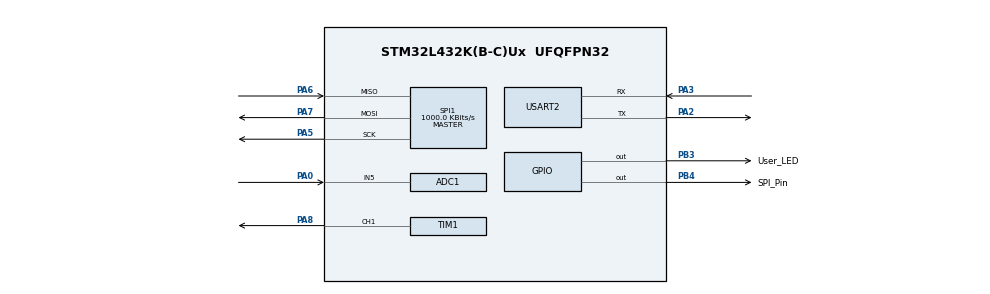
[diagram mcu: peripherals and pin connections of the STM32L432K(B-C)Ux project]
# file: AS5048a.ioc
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ADC1.Channel-1\#ChannelRegularConversion=ADC_CHANNEL_5
ADC1.NbrOfConversion=1
ADC1.NbrOfConversionFlag=1
ADC1.OffsetNumber-1\#ChannelRegularConversion=ADC_OFFSET_NONE
ADC1.Rank-1\#ChannelRegularConversion=1
ADC1.SamplingTime-1\#ChannelRegularConversion=ADC_SAMPLETIME_2CYCLES_5
ADC1.master=1
Mcu.Family=STM32L4
Mcu.Name=STM32L432K(B-C)Ux
Mcu.Package=UFQFPN32
NVIC.PriorityGroup=NVIC_PRIORITYGROUP_4
PA0.Signal=ADCx_IN5
PA2.Mode=Asynchronous
PA2.Signal=USART2_TX
PA3.Mode=Asynchronous
PA3.Signal=USART2_RX
PA5.Mode=Full_Duplex_Master
PA5.Signal=SPI1_SCK
PA6.Mode=Full_Duplex_Master
PA6.Signal=SPI1_MISO
PA7.Mode=Full_Duplex_Master
PA7.Signal=SPI1_MOSI
PA8.Signal=S_TIM1_CH1
PB3\ (JTDO-TRACESWO).GPIO_Label=User_LED
PB3\ (JTDO-TRACESWO).Signal=GPIO_Output
PB4\ (NJTRST).GPIO_Label=SPI_Pin
PB4\ (NJTRST).Signal=GPIO_Output
ProjectManager.HeapSize=0x200
ProjectManager.StackSize=0x400
ProjectManager.TargetToolchain=Makefile
RCC.ADCFreq_Value=32000000
RCC.HSE_VALUE=8000000
RCC.HSI48_VALUE=48000000
RCC.HSI_VALUE=16000000
RCC.LSE_VALUE=32768
RCC.MSI_VALUE=4000000
RCC.PLLSAI1N=16
RCC.USBFreq_Value=32000000
RCC.VCOOutputFreq_Value=32000000
SH.ADCx_IN5.0=ADC1_IN5,IN5-Single-Ended
SH.S_TIM1_CH1.0=TIM1_CH1,PWM Generation1 CH1
SPI1.BaudRatePrescaler=SPI_BAUDRATEPRESCALER_4
SPI1.CalculateBaudRate=1000.0 KBits/s
SPI1.DataSize=SPI_DATASIZE_16BIT
SPI1.Direction=SPI_DIRECTION_2LINES
SPI1.Mode=SPI_MODE_MASTER
SPI1.VirtualType=VM_MASTER
TIM1.Channel-PWM\ Generation1\ CH1=TIM_CHANNEL_1
TIM1.Prescaler=3
USART2.VirtualMode-Asynchronous=VM_ASYNC
VP_TIM1_VS_ClockSourceINT.Mode=Internal
board=custom

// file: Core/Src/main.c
/* USER CODE BEGIN Header */
/**
  ******************************************************************************
  * @file           : main.c
  * @brief          : Main program body
  ******************************************************************************
  * @attention
  *
  * Copyright (c) 2025 STMicroelectronics.
  * All rights reserved.
  *
  * This software is licensed under terms that can be found in the LICENSE file
  * in the root directory of this software component.
  * If no LICENSE file comes with this software, it is provided AS-IS.
  *
  ******************************************************************************
  */
/* USER CODE END Header */
#include "main.h"
#include "adc.h"
#include "spi.h"
#include "tim.h"
#include "usart.h"
#include "gpio.h"

/* USER CODE BEGIN Includes */
#include <string.h>
/* USER CODE END Includes */

void SystemClock_Config(void);

int main(void)
{

  /* MCU Configuration--------------------------------------------------------*/

  /* Reset of all peripherals, Initializes the Flash interface and the Systick. */
  HAL_Init();

  /* Configure the system clock */
  SystemClock_Config();

  /* Initialize all configured peripherals */
  MX_GPIO_Init();
  MX_ADC1_Init();
  MX_SPI1_Init();
  MX_TIM1_Init();
  MX_USART2_UART_Init();

  /* Infinite loop */
  /* USER CODE BEGIN WHILE */
  while (1)
  {
    // HAL_GPIO_WritePin(User_LED_GPIO_Port, User_LED_Pin, GPIO_PIN_SET);
    // HAL_Delay(1000);
    // HAL_GPIO_WritePin(User_LED_GPIO_Port, User_LED_Pin, GPIO_PIN_RESET);
    // HAL_Delay(1000);
    // uint8_t msg[] = "hello world!\n\r";
    // HAL_UART_Transmit(&huart2, msg, strlen((char*)msg), 100);

    /* USER CODE END WHILE */

  }
}

void SystemClock_Config(void)
{
  RCC_OscInitTypeDef RCC_OscInitStruct = {0};
  RCC_ClkInitTypeDef RCC_ClkInitStruct = {0};

  /** Configure the main internal regulator output voltage
  */
  if (HAL_PWREx_ControlVoltageScaling(PWR_REGULATOR_VOLTAGE_SCALE1) != HAL_OK)
  {
    Error_Handler();
  }

  /** Initializes the RCC Oscillators according to the specified parameters
  * in the RCC_OscInitTypeDef structure.
  */
  RCC_OscInitStruct.OscillatorType = RCC_OSCILLATORTYPE_MSI;
  RCC_OscInitStruct.MSIState = RCC_MSI_ON;
  RCC_OscInitStruct.MSICalibrationValue = 0;
  RCC_OscInitStruct.MSIClockRange = RCC_MSIRANGE_6;
  RCC_OscInitStruct.PLL.PLLState = RCC_PLL_NONE;
  if (HAL_RCC_OscConfig(&RCC_OscInitStruct) != HAL_OK)
  {
    Error_Handler();
  }

  /** Initializes the CPU, AHB and APB buses clocks
  */
  RCC_ClkInitStruct.ClockType = RCC_CLOCKTYPE_HCLK|RCC_CLOCKTYPE_SYSCLK
                              |RCC_CLOCKTYPE_PCLK1|RCC_CLOCKTYPE_PCLK2;
  RCC_ClkInitStruct.SYSCLKSource = RCC_SYSCLKSOURCE_MSI;
  RCC_ClkInitStruct.AHBCLKDivider = RCC_SYSCLK_DIV1;
  RCC_ClkInitStruct.APB1CLKDivider = RCC_HCLK_DIV1;
  RCC_ClkInitStruct.APB2CLKDivider = RCC_HCLK_DIV1;

  if (HAL_RCC_ClockConfig(&RCC_ClkInitStruct, FLASH_LATENCY_0) != HAL_OK)
  {
    Error_Handler();
  }
}

void Error_Handler(void)
{
  __disable_irq();
  while (1)
  {
  }
}
